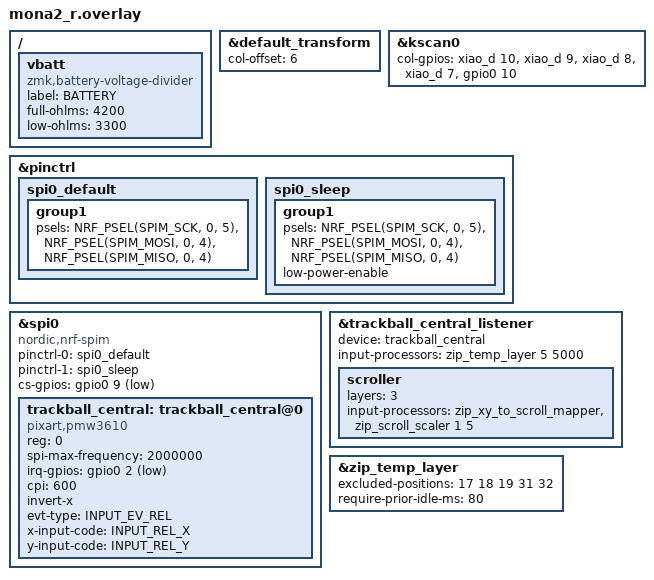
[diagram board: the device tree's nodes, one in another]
#include "mona2.dtsi"
#include <input/processors.dtsi>
#include <zephyr/dt-bindings/input/input-event-codes.h>

/ {
    /* バッテリーの100%と0%の電圧範囲を定義 */
    /* ZMKはこの値を参照してパーセンテージを計算します */
    vbatt {
        compatible = "zmk,battery-voltage-divider";
        label = "BATTERY";
        full-ohlms = <4200>; // 100% = 4.2V
        low-ohlms = <3300>;  // 0% = 3.3V (電池保護のため少し高め)
    };
};

&default_transform {
    col-offset = <6>;
};

&kscan0 {
    col-gpios
        = <&xiao_d 10 GPIO_ACTIVE_HIGH>
        , <&xiao_d 9 GPIO_ACTIVE_HIGH> 
        , <&xiao_d 8 GPIO_ACTIVE_HIGH> 
        , <&xiao_d 7 GPIO_ACTIVE_HIGH> 
        , <&gpio0 10 GPIO_ACTIVE_HIGH>
        ;
};

&pinctrl {
    // 【通常動作時】トラックボールと通信するためのピン割り当て
    spi0_default: spi0_default {
        group1 {
            // P0.05 = SCLK (通信クロック)
            // P0.04 = SDIO (データ入出力) ※MOSI/MISO共通化
            psels = <NRF_PSEL(SPIM_SCK, 0, 5)>, 
                    <NRF_PSEL(SPIM_MOSI, 0, 4)>, 
                    <NRF_PSEL(SPIM_MISO, 0, 4)>;
        };
    };

    // 【スリープ時】電力消費を最小限に抑えるためのピン割り当て
    spi0_sleep: spi0_sleep {
        group1 {
            psels = <NRF_PSEL(SPIM_SCK, 0, 5)>,
                    <NRF_PSEL(SPIM_MOSI, 0, 4)>,
                    <NRF_PSEL(SPIM_MISO, 0, 4)>;
            low-power-enable; // ← 無線運用時のバッテリー持ちに直結する重要設定
        };
    };
};

&spi0 {
    status = "okay";
    compatible = "nordic,nrf-spim";
    pinctrl-0 = <&spi0_default>;
    pinctrl-1 = <&spi0_sleep>;
    pinctrl-names = "default", "sleep";
    cs-gpios = <&gpio0 9 GPIO_ACTIVE_LOW>;

    trackball_central: trackball_central@0 {
        status = "okay";
        compatible = "pixart,pmw3610";
        reg = <0>;
        spi-max-frequency = <2000000>;
        irq-gpios = <&gpio0 2 (GPIO_ACTIVE_LOW | GPIO_PULL_UP)>;
        cpi = <600>; // カーソル速度（数値が高いほど速い）

        // --- マウスの向き設定 (COROPIT対応) ---
        invert-x; // X軸反転（左右が逆ならコメントアウト）
        //invert-y; // Y軸反転（上下が逆ならコメントアウト）
        // swap-xy; // X軸とY軸を入れ替える場合はコメントアウトを外す

        evt-type = <INPUT_EV_REL>;
        x-input-code = <INPUT_REL_X>;
        y-input-code = <INPUT_REL_Y>;
    };
};

&trackball_central_listener {
    status = "okay";
    device = <&trackball_central>;

    // 【マウス動作の基本プロセス】
    input-processors = 
        <&zip_temp_layer 5 5000>; // [判定] レイヤー5を5秒間維持
        // 必要に応じてここに <&zip_xy_transform INPUT_TRANSFORM_X_INVERT> 等を追記可能

    scroller {
        layers = <3>; // レイヤー3の時だけスクロールモード
        input-processors = 
            <&zip_xy_to_scroll_mapper>, // ボール移動をスクロールに変換
            // <&zip_scroll_transform INPUT_TRANSFORM_X_INVERT>, // スクロール方向だけ反転したい場合
            <&zip_scroll_scaler 1 5>;   // スクロール速度調整 (分子 分母)
    };
};

&zip_temp_layer {
    // [17:J, 18:K, 19:L, 31:MB4, 32:MB5] マウス操作中にレイヤーを維持するキー番号
    excluded-positions = <17 18 19 31 32>; 
    
    // タイピング終了からマウス反応までの待機時間(ms)
    require-prior-idle-ms = <80>;
};
